# CM4_ICFG register map
Vendor: Texas Instruments
Peripheral module from a debugger description file (folder am273).
Registers are 32-bit, read-only, no defined reset value unless marked. A register's access mark holds for its fields unless they carry their own. Offsets are as the file gives them; lines under a group give offsets from that group; [hi:lo] are bit positions; {n}, {i} and the like mark numbered series; 'fields as' and 'values as' point back to an identical list; <NAME> marks a mode.

## CM4_ICFG
0x00 CMX_ITM_STIM0 rw — http://infocenter.arm.com/help/topic/com.arm.doc.ddi0439b/DDI0439B_cortex_m4_r0p0_trm.pdf
  [31:0] ITM_STIM0 — RW - ITM_STIM0
0x7C CMX_ITM_STIM31 rw — http://infocenter.arm.com/help/topic/com.arm.doc.ddi0439b/DDI0439B_cortex_m4_r0p0_trm.pdf
  [31:0] ITM_STIM31 — RW - ITM_STIM31
0xE00 CMX_ITM_TER rw — http://infocenter.arm.com/help/topic/com.arm.doc.ddi0439b/DDI0439B_cortex_m4_r0p0_trm.pdf
  [31:0] ITM_TER — RW 0x00000000 Trace Enable Register
0xE40 CMX_ITM_TPR rw — http://infocenter.arm.com/help/topic/com.arm.doc.ddi0439b/DDI0439B_cortex_m4_r0p0_trm.pdf
  [31:0] ITM_TPR — RW 0x00000000 ITM Trace Privilege Register, ITM_TPR on page 10-5
0xE80 CMX_ITM_TCR rw — http://infocenter.arm.com/help/topic/com.arm.doc.ddi0439b/DDI0439B_cortex_m4_r0p0_trm.pdf
  [31:0] ITM_TCR — RW 0x00000000 Trace Control Register
0xEF8 CMX_ITM_IWR access per field — ITM Integration Write Register (privileged access only)
  [0] ATVALIDM rw — Write Only. Only use with integration test (on-chip connectivity test). Do not use in normal applications. When in integration test mode, i.e., bit 0 of ITM->IMCR is set, this bit is used to control the ATVALIDM output of the ATB (trace bus)
0xEFC CMX_ITM_IRR — ITM Integration Read Register (privileged access only)
  [0] ATREADYM — Only use with integration test (on-chip connectivity test). Do not use in normal applications. When in integration test mode, i.e. bit 0 of ITM->IMCR is set, this bit is used to read the ATREADYM input of the ATB (trace bus)
0xF00 CMX_ITM_IMCR access per field — ITM Integration Mode Control Register (privileged access only)
  [0] INTEGRATION rw — Only use with integration test (on-chip connectivity test). Do not use in normal applications. Set to 1 to enable integration test mode.
0xFB0 CMX_LAR rw — https://static.docs.arm.com/ihi0029/e/coresight_v3_0_architecture_specification_IHI0029E.pdf?_ga=2.243641541.19024475.1571741864-233759942.1562499274
  [31:0] KEY — Writing a value to this field controls write access to the other registers in the component. Permitted values of KEY are: Write 0xC5ACCE55 Signals that LSR must permit writing to the other registers in the component. Write any other value Signals that LSR must block writing to the other registers in the component.
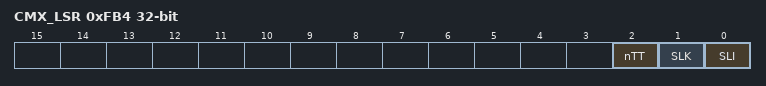
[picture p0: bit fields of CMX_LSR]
0xFB4 CMX_LSR access per field — https://static.docs.arm.com/ihi0029/e/coresight_v3_0_architecture_specification_IHI0029E.pdf?_ga=2.243641541.19024475.1571741864-233759942.1562499274
  [2] nTT rw — This bit is always zero, which indicates that the component implements a 32-bit LAR
  [1] SLK rw — This field is used to return the current software lock status. Permitted values of SLK are: 0 Writing to the other registers in the component is permitted. 1 Writing to the other registers in the component is blocked.
  [0] SLI rw — This field indicates whether a Software lock mechanism is implemented. Permitted values of SLI are: 0 Software lock mechanism is not implemented. 1 Software lock mechanism is implemented.
0xFD0 CMX_ITM_PID4 — http://infocenter.arm.com/help/topic/com.arm.doc.ddi0439b/DDI0439B_cortex_m4_r0p0_trm.pdf
  [31:0] ITM_PID4 — RO 0x00000004 Peripheral Identification registers
{0xFC0+4i} CMX_ITM_PID{i} (i=5..7) — http://infocenter.arm.com/help/topic/com.arm.doc.ddi0439b/DDI0439B_cortex_m4_r0p0_trm.pdf
  [31:0] ITM_PID{i} — RO 0x00000000
0xFE0 CMX_ITM_PID0 — http://infocenter.arm.com/help/topic/com.arm.doc.ddi0439b/DDI0439B_cortex_m4_r0p0_trm.pdf
  [31:0] ITM_PID0 — RO 0x00000001
0xFE4 CMX_ITM_PID1 — http://infocenter.arm.com/help/topic/com.arm.doc.ddi0439b/DDI0439B_cortex_m4_r0p0_trm.pdf
  [31:0] ITM_PID1 — RO 0x000000B0
0xFE8 CMX_ITM_PID2 — http://infocenter.arm.com/help/topic/com.arm.doc.ddi0439b/DDI0439B_cortex_m4_r0p0_trm.pdf
  [31:0] ITM_PID2 — RO 0x0000003B
0xFEC CMX_ITM_PID3 — http://infocenter.arm.com/help/topic/com.arm.doc.ddi0439b/DDI0439B_cortex_m4_r0p0_trm.pdf
  [31:0] ITM_PID3 — RO 0x00000000
0xFF0 CMX_ITM_CID0 — http://infocenter.arm.com/help/topic/com.arm.doc.ddi0439b/DDI0439B_cortex_m4_r0p0_trm.pdf
  [31:0] ITM_CID0 — RO 0x0000000D Component Identification registers
0xFF4 CMX_ITM_CID1 — http://infocenter.arm.com/help/topic/com.arm.doc.ddi0439b/DDI0439B_cortex_m4_r0p0_trm.pdf
  [31:0] ITM_CID1 — RO 0x000000E0
0xFF8 CMX_ITM_CID2 — http://infocenter.arm.com/help/topic/com.arm.doc.ddi0439b/DDI0439B_cortex_m4_r0p0_trm.pdf
  [31:0] ITM_CID2 — RO 0x00000005
0xFFC CMX_ITM_CID3 — http://infocenter.arm.com/help/topic/com.arm.doc.ddi0439b/DDI0439B_cortex_m4_r0p0_trm.pdf
  [31:0] ITM_CID3 — RO 0x000000B1
0x1000 CMX_DWT_CTRL rw — http://infocenter.arm.com/help/topic/com.arm.doc.ddi0439b/DDI0439B_cortex_m4_r0p0_trm.pdf
  [31:0] DWT_CTRL — RW See a Control Register
0x1004 CMX_DWT_CYCCNT rw — http://infocenter.arm.com/help/topic/com.arm.doc.ddi0439b/DDI0439B_cortex_m4_r0p0_trm.pdf
  [31:0] DWT_CYCCNT — RW 0x00000000 Cycle Count Register
0x1008 CMX_DWT_CPICNT rw — http://infocenter.arm.com/help/topic/com.arm.doc.ddi0439b/DDI0439B_cortex_m4_r0p0_trm.pdf
  [31:0] DWT_CPICNT — RW - CPI Count Register
0x100C CMX_DWT_EXCCNT rw — http://infocenter.arm.com/help/topic/com.arm.doc.ddi0439b/DDI0439B_cortex_m4_r0p0_trm.pdf
  [31:0] DWT_EXCCNT — RW - Exception Overhead Count Register
0x1010 CMX_DWT_SLEEPCNT rw — http://infocenter.arm.com/help/topic/com.arm.doc.ddi0439b/DDI0439B_cortex_m4_r0p0_trm.pdf
  [31:0] DWT_SLEEPCNT — RW - Sleep Count Register
0x1014 CMX_DWT_LSUCNT rw — http://infocenter.arm.com/help/topic/com.arm.doc.ddi0439b/DDI0439B_cortex_m4_r0p0_trm.pdf
  [31:0] DWT_LSUCNT — RW - LSU Count Register
0x1018 CMX_DWT_FOLDCNT rw — http://infocenter.arm.com/help/topic/com.arm.doc.ddi0439b/DDI0439B_cortex_m4_r0p0_trm.pdf
  [31:0] DWT_FOLDCNT — RW - Folded-instruction Count Register
0x101C CMX_DWT_PCSR — http://infocenter.arm.com/help/topic/com.arm.doc.ddi0439b/DDI0439B_cortex_m4_r0p0_trm.pdf
  [31:0] DWT_PCSR — RO - Program Counter Sample Register
{0x1020+0x10*i} CMX_DWT_COMP{i} rw (i=0..3) — http://infocenter.arm.com/help/topic/com.arm.doc.ddi0439b/DDI0439B_cortex_m4_r0p0_trm.pdf
  [31:0] DWT_COMP{i} — RW - Comparator Register{i}
{0x1024+0x10*i} CMX_DWT_MASK{i} rw (i=0..3) — http://infocenter.arm.com/help/topic/com.arm.doc.ddi0439b/DDI0439B_cortex_m4_r0p0_trm.pdf
  [31:0] DWT_MASK{i} — RW - Mask Register{i}
{0x1028+0x10*i} CMX_DWT_FUNCTION{i} rw (i=0..3) — http://infocenter.arm.com/help/topic/com.arm.doc.ddi0439b/DDI0439B_cortex_m4_r0p0_trm.pdf
  [31:0] DWT_FUNCTION{i} — RW 0x00000000 Function Register{i}
0x1FD0 CMX_DWT_PID4 — http://infocenter.arm.com/help/topic/com.arm.doc.ddi0439b/DDI0439B_cortex_m4_r0p0_trm.pdf
  [31:0] DWT_PID4 — RO 0x04 Peripheral identification registers
{0x1FC0+4i} CMX_DWT_PID{i} (i=5..7) — http://infocenter.arm.com/help/topic/com.arm.doc.ddi0439b/DDI0439B_cortex_m4_r0p0_trm.pdf
  [31:0] DWT_PID{i} — RO 0x00
0x1FE0 CMX_DWT_PID0 — http://infocenter.arm.com/help/topic/com.arm.doc.ddi0439b/DDI0439B_cortex_m4_r0p0_trm.pdf
  [31:0] DWT_PID0 — RO 0x02
0x1FE4 CMX_DWT_PID1 — http://infocenter.arm.com/help/topic/com.arm.doc.ddi0439b/DDI0439B_cortex_m4_r0p0_trm.pdf
  [31:0] DWT_PID1 — RO 0xB0
0x1FE8 CMX_DWT_PID2 — http://infocenter.arm.com/help/topic/com.arm.doc.ddi0439b/DDI0439B_cortex_m4_r0p0_trm.pdf
  [31:0] DWT_PID2 — RO 0x3B
0x1FEC CMX_DWT_PID3 — http://infocenter.arm.com/help/topic/com.arm.doc.ddi0439b/DDI0439B_cortex_m4_r0p0_trm.pdf
  [31:0] DWT_PID3 — RO 0x00
0x1FF0 CMX_DWT_CID0 — http://infocenter.arm.com/help/topic/com.arm.doc.ddi0439b/DDI0439B_cortex_m4_r0p0_trm.pdf
  [31:0] DWT_CID0 — RO 0x0D Component identification registers
0x1FF4 CMX_DWT_CID1 — http://infocenter.arm.com/help/topic/com.arm.doc.ddi0439b/DDI0439B_cortex_m4_r0p0_trm.pdf
  [31:0] DWT_CID1 — RO 0xE0
0x1FF8 CMX_DWT_CID2 — http://infocenter.arm.com/help/topic/com.arm.doc.ddi0439b/DDI0439B_cortex_m4_r0p0_trm.pdf
  [31:0] DWT_CID2 — RO 0x05
0x1FFC CMX_DWT_CID3 — http://infocenter.arm.com/help/topic/com.arm.doc.ddi0439b/DDI0439B_cortex_m4_r0p0_trm.pdf
  [31:0] DWT_CID3 — RO 0xB1
0x2000 CMX_FP_CTRL rw — http://infocenter.arm.com/help/topic/com.arm.doc.ddi0439b/DDI0439B_cortex_m4_r0p0_trm.pdf
  [31:0] FP_CTRL — RW 0x130 FlashPatch Control Register
0x2004 CMX_FP_REMAP rw — http://infocenter.arm.com/help/topic/com.arm.doc.ddi0439b/DDI0439B_cortex_m4_r0p0_trm.pdf
  [31:0] FP_REMAP — RW - FlashPatch Remap Register
0x2008 CMX_FP_COMP0 rw — http://infocenter.arm.com/help/topic/com.arm.doc.ddi0439b/DDI0439B_cortex_m4_r0p0_trm.pdf
  [31:0] FP_COMP0 — RW 1'b0a . For FP_COMP0 to FP_COMP7, bit 0 is reset to 0. Other bits in these registers are FlashPatch Comparator Register0
{0x2008+4i} CMX_FP_COMP{i} rw (i=1..7) — http://infocenter.arm.com/help/topic/com.arm.doc.ddi0439b/DDI0439B_cortex_m4_r0p0_trm.pdf
  [31:0] FP_COMP{i} — RW 1'b0 FlashPatch Comparator Register{i}
0x2FD0 CMX_FP_PID4 — http://infocenter.arm.com/help/topic/com.arm.doc.ddi0439b/DDI0439B_cortex_m4_r0p0_trm.pdf
  [31:0] FP_PID4 — RO 0x04 Peripheral identification registers
{0x2FC0+4i} CMX_FP_PID{i} (i=5..7) — http://infocenter.arm.com/help/topic/com.arm.doc.ddi0439b/DDI0439B_cortex_m4_r0p0_trm.pdf
  [31:0] FP_PID{i} — RO 0x00
0x2FE0 CMX_FP_PID0 — http://infocenter.arm.com/help/topic/com.arm.doc.ddi0439b/DDI0439B_cortex_m4_r0p0_trm.pdf
  [31:0] FP_PID0 — RO 0x03
0x2FE4 CMX_FP_PID1 — http://infocenter.arm.com/help/topic/com.arm.doc.ddi0439b/DDI0439B_cortex_m4_r0p0_trm.pdf
  [31:0] FP_PID1 — RO 0xB0
0x2FE8 CMX_FP_PID2 — http://infocenter.arm.com/help/topic/com.arm.doc.ddi0439b/DDI0439B_cortex_m4_r0p0_trm.pdf
  [31:0] FP_PID2 — RO 0x2B
0x2FEC CMX_FP_PID3 — http://infocenter.arm.com/help/topic/com.arm.doc.ddi0439b/DDI0439B_cortex_m4_r0p0_trm.pdf
  [31:0] FP_PID3 — RO 0x00
0x2FF0 CMX_FP_CID0 — http://infocenter.arm.com/help/topic/com.arm.doc.ddi0439b/DDI0439B_cortex_m4_r0p0_trm.pdf
  [31:0] FP_CID0 — RO 0x0D Component identification registers
0x2FF4 CMX_FP_CID1 — http://infocenter.arm.com/help/topic/com.arm.doc.ddi0439b/DDI0439B_cortex_m4_r0p0_trm.pdf
  [31:0] FP_CID1 — RO 0xE0
0x2FF8 CMX_FP_CID2 — http://infocenter.arm.com/help/topic/com.arm.doc.ddi0439b/DDI0439B_cortex_m4_r0p0_trm.pdf
  [31:0] FP_CID2 — RO 0x05
0x2FFC CMX_FP_CID3 — http://infocenter.arm.com/help/topic/com.arm.doc.ddi0439b/DDI0439B_cortex_m4_r0p0_trm.pdf
  [31:0] FP_CID3 — RO 0xB1
0xE008 CMX_ACTLR rw — http://infocenter.arm.com/help/topic/com.arm.doc.ddi0439b/DDI0439B_cortex_m4_r0p0_trm.pdf
  [31:0] ACTLR — RW 0x00000000 Auxiliary Control Register, ACTLR on page 4-5
0xE010 CMX_STCSR rw — http://infocenter.arm.com/help/topic/com.arm.doc.ddi0439b/DDI0439B_cortex_m4_r0p0_trm.pdf
  [31:0] STCSR — RW 0x00000000 SysTick Control and Status Register
0xE014 CMX_STRVR rw — http://infocenter.arm.com/help/topic/com.arm.doc.ddi0439b/DDI0439B_cortex_m4_r0p0_trm.pdf
  [31:0] STRVR — RW Unknown SysTick Reload Value Register
0xE018 CMX_STCVR rw — http://infocenter.arm.com/help/topic/com.arm.doc.ddi0439b/DDI0439B_cortex_m4_r0p0_trm.pdf
  [31:0] STCVR — RW clear Unknown SysTick Current Value Register
0xE01C CMX_STCR — http://infocenter.arm.com/help/topic/com.arm.doc.ddi0439b/DDI0439B_cortex_m4_r0p0_trm.pdf
  [31:0] STCR — RO STCALIB SysTick Calibration Value Register
0xED00 CMX_CPUID — http://infocenter.arm.com/help/topic/com.arm.doc.ddi0439b/DDI0439B_cortex_m4_r0p0_trm.pdf
  [31:0] CPUID — RO 0x410FC240 CPUID Base Register, CPUID on page 4-5
0xED04 CMX_ICSR rw — http://infocenter.arm.com/help/topic/com.arm.doc.ddi0439b/DDI0439B_cortex_m4_r0p0_trm.pdf
  [31:0] ICSR — RW or RO 0x00000000 Interrupt Control and State Register
0xED08 CMX_VTOR rw — http://infocenter.arm.com/help/topic/com.arm.doc.ddi0439b/DDI0439B_cortex_m4_r0p0_trm.pdf
  [31:0] VTOR — RW 0x00000000 Vector Table Offset Register
0xED0C CMX_AIRCR rw — http://infocenter.arm.com/help/topic/com.arm.doc.ddi0439b/DDI0439B_cortex_m4_r0p0_trm.pdf
  [31:0] AIRCR — RW 0x00000000a Application Interrupt and Reset Control Register
0xED10 CMX_SCR rw — http://infocenter.arm.com/help/topic/com.arm.doc.ddi0439b/DDI0439B_cortex_m4_r0p0_trm.pdf
  [31:0] SCR — RW 0x00000000 System Control Register
0xED14 CMX_CCR rw — http://infocenter.arm.com/help/topic/com.arm.doc.ddi0439b/DDI0439B_cortex_m4_r0p0_trm.pdf
  [31:0] CCR — RW 0x00000200 Configuration and Control Register.
{0xED14+4i} CMX_SHPR{i} rw (i=1..3) — http://infocenter.arm.com/help/topic/com.arm.doc.ddi0439b/DDI0439B_cortex_m4_r0p0_trm.pdf
  [31:0] SHPR{i} — RW 0x00000000 System Handler Priority Register {i}
0xED24 CMX_SHCSR rw — http://infocenter.arm.com/help/topic/com.arm.doc.ddi0439b/DDI0439B_cortex_m4_r0p0_trm.pdf
  [31:0] SHCSR — RW 0x00000000 System Handler Control and State Register
0xED28 CMX_CFSR rw — http://infocenter.arm.com/help/topic/com.arm.doc.ddi0439b/DDI0439B_cortex_m4_r0p0_trm.pdf
  [31:0] CFSR — RW 0x00000000 Configurable Fault Status Registers
0xED2C CMX_HFSR rw — http://infocenter.arm.com/help/topic/com.arm.doc.ddi0439b/DDI0439B_cortex_m4_r0p0_trm.pdf
  [31:0] HFSR — RW 0x00000000 HardFault Status register
0xED30 CMX_DFSR rw — http://infocenter.arm.com/help/topic/com.arm.doc.ddi0439b/DDI0439B_cortex_m4_r0p0_trm.pdf
  [31:0] DFSR — RW 0x00000000 Debug Fault Status Register
0xED34 CMX_MMFAR rw — http://infocenter.arm.com/help/topic/com.arm.doc.ddi0439b/DDI0439B_cortex_m4_r0p0_trm.pdf
  [31:0] MMFAR — RW Unknown MemManage Address Registerb
0xED38 CMX_BFAR rw — http://infocenter.arm.com/help/topic/com.arm.doc.ddi0439b/DDI0439B_cortex_m4_r0p0_trm.pdf
  [31:0] BFAR — RW Unknown BusFault Address Registerb
0xED3C CMX_AFSR rw — http://infocenter.arm.com/help/topic/com.arm.doc.ddi0439b/DDI0439B_cortex_m4_r0p0_trm.pdf
  [31:0] AFSR — RW 0x00000000 Auxiliary Fault Status Register, AFSR on page 4-6
0xED40 CMX_ID_PFR0 — http://infocenter.arm.com/help/topic/com.arm.doc.ddi0439b/DDI0439B_cortex_m4_r0p0_trm.pdf
  [31:0] ID_PFR0 — RO 0x00000030 Processor Feature Register 0
0xED44 CMX_ID_PFR1 — http://infocenter.arm.com/help/topic/com.arm.doc.ddi0439b/DDI0439B_cortex_m4_r0p0_trm.pdf
  [31:0] ID_PFR1 — RO 0x00000200 Processor Feature Register 1
0xED48 CMX_ID_DFR0 — http://infocenter.arm.com/help/topic/com.arm.doc.ddi0439b/DDI0439B_cortex_m4_r0p0_trm.pdf
  [31:0] ID_DFR0 — RO 0x00100000 Debug Features Register 0
0xED4C CMX_ID_AFR0 — http://infocenter.arm.com/help/topic/com.arm.doc.ddi0439b/DDI0439B_cortex_m4_r0p0_trm.pdf
  [31:0] ID_AFR0 — RO 0x00000000 Auxiliary Features Register 0
0xED50 CMX_ID_MMFR0 — http://infocenter.arm.com/help/topic/com.arm.doc.ddi0439b/DDI0439B_cortex_m4_r0p0_trm.pdf
  [31:0] ID_MMFR0 — RO 0x00000030 Memory Model Feature Register 0
{0xED50+4i} CMX_ID_MMFR{i} (i=1..3) — http://infocenter.arm.com/help/topic/com.arm.doc.ddi0439b/DDI0439B_cortex_m4_r0p0_trm.pdf
  [31:0] ID_MMFR{i} — RO 0x00000000 Memory Model Feature Register {i}
0xED60 CMX_ID_ISAR0 — http://infocenter.arm.com/help/topic/com.arm.doc.ddi0439b/DDI0439B_cortex_m4_r0p0_trm.pdf
  [31:0] ID_ISAR0 — RO 0x01141110 Instruction Set Attributes Register 0
0xED64 CMX_ID_ISAR1 — http://infocenter.arm.com/help/topic/com.arm.doc.ddi0439b/DDI0439B_cortex_m4_r0p0_trm.pdf
  [31:0] ID_ISAR1 — RO 0x02112000 Instruction Set Attributes Register 1
0xED68 CMX_ID_ISAR2 — http://infocenter.arm.com/help/topic/com.arm.doc.ddi0439b/DDI0439B_cortex_m4_r0p0_trm.pdf
  [31:0] ID_ISAR2 — RO 0x21232231 Instruction Set Attributes Register 2
0xED6C CMX_ID_ISAR3 — http://infocenter.arm.com/help/topic/com.arm.doc.ddi0439b/DDI0439B_cortex_m4_r0p0_trm.pdf
  [31:0] ID_ISAR3 — RO 0x01111131 Instruction Set Attributes Register 3
0xED70 CMX_ID_ISAR4 — http://infocenter.arm.com/help/topic/com.arm.doc.ddi0439b/DDI0439B_cortex_m4_r0p0_trm.pdf
  [31:0] ID_ISAR4 — RO 0x01310102 Instruction Set Attributes Register 4
0xED88 CMX_CPACR rw — http://infocenter.arm.com/help/topic/com.arm.doc.ddi0439b/DDI0439B_cortex_m4_r0p0_trm.pdf
  [31:0] CPACR — RW - Coprocessor Access Control Register
0xEDF0 CMX_DHCSR rw — http://infocenter.arm.com/help/topic/com.arm.doc.ddi0439b/DDI0439B_cortex_m4_r0p0_trm.pdf
  [31:0] DHCSR — RW -- DBG -- Debug Halt Control and Status Register
0xEDF4 CMX_DCRSR wo — http://infocenter.arm.com/help/topic/com.arm.doc.ddi0439b/DDI0439B_cortex_m4_r0p0_trm.pdf
  [31:0] DCRSR — W -- DBG -- Debug Core Register Selector Register
0xEDF8 CMX_DCRDR rw — http://infocenter.arm.com/help/topic/com.arm.doc.ddi0439b/DDI0439B_cortex_m4_r0p0_trm.pdf
  [31:0] DCRDR — RW -- DBG -- Debug Core Register Data Register
0xEDFC CMX_DEMCR rw — http://infocenter.arm.com/help/topic/com.arm.doc.ddi0439b/DDI0439B_cortex_m4_r0p0_trm.pdf
  [31:0] DEMCR — RW -- DBG -- Debug Exception and Monitor Control Register
0xEF00 CMX_STIR wo — http://infocenter.arm.com/help/topic/com.arm.doc.ddi0439b/DDI0439B_cortex_m4_r0p0_trm.pdf
  [31:0] STIR — WO 0x00000000 Software Triggered Interrupt Register
0x40000 CMX_TPIU_SSPSR — http://infocenter.arm.com/help/topic/com.arm.doc.ddi0439b/DDI0439B_cortex_m4_r0p0_trm.pdf
  [31:0] TPIU_SSPSR — RO 0x0xx Supported Synchronous Port Size Register
0x40004 CMX_TPIU_CSPSR rw — http://infocenter.arm.com/help/topic/com.arm.doc.ddi0439b/DDI0439B_cortex_m4_r0p0_trm.pdf
  [31:0] TPIU_CSPSR — RW 0x01 Current Synchronous Port Size Register
0x40010 CMX_TPIU_ACPR rw — http://infocenter.arm.com/help/topic/com.arm.doc.ddi0439b/DDI0439B_cortex_m4_r0p0_trm.pdf
  [31:0] TPIU_ACPR — RW 0x0000 Asynchronous Clock Prescaler Register, TPIU_ACPR on page 11-6
0x400F0 CMX_TPIU_SPPR rw — http://infocenter.arm.com/help/topic/com.arm.doc.ddi0439b/DDI0439B_cortex_m4_r0p0_trm.pdf
  [31:0] TPIU_SPPR — RW 0x01 Selected Pin Protocol Register
0x40300 CMX_TPIU_FFSR — http://infocenter.arm.com/help/topic/com.arm.doc.ddi0439b/DDI0439B_cortex_m4_r0p0_trm.pdf
  [31:0] TPIU_FFSR — RO 0x08 Formatter and Flush Status Register, TPIU_FFSR on page 11-6
0x40304 CMX_TPIU_FFCR rw — http://infocenter.arm.com/help/topic/com.arm.doc.ddi0439b/DDI0439B_cortex_m4_r0p0_trm.pdf
  [31:0] TPIU_FFCR — RW 0x102 Formatter and Flush Control Register, TPIU_FFCR on page 11-7
0x40308 CMX_TPIU_FSCR — http://infocenter.arm.com/help/topic/com.arm.doc.ddi0439b/DDI0439B_cortex_m4_r0p0_trm.pdf
  [31:0] TPIU_FSCR — RO 0x00 Formatter Synchronization Counter Register
0x40EE8 CMX_TPIU_TRIGGER — http://infocenter.arm.com/help/topic/com.arm.doc.ddi0439b/DDI0439B_cortex_m4_r0p0_trm.pdf
  [31:0] TPIU_TRIGGER — RO 0x0 TRIGGER on page 11-8
0x40EEC CMX_TPIU_FIFO_DATA0 — http://infocenter.arm.com/help/topic/com.arm.doc.ddi0439b/DDI0439B_cortex_m4_r0p0_trm.pdf
  [31:0] TPIU_FIFO_DATA0 — RO 0x--000000 Integration ETM Data on page 11-8
0x40EF0 CMX_TPIU_ITATBCTR2 — http://infocenter.arm.com/help/topic/com.arm.doc.ddi0439b/DDI0439B_cortex_m4_r0p0_trm.pdf
  [31:0] TPIU_ITATBCTR2 — RO 0x0 ITATBCTR2 on page 11-9
0x40EF8 CMX_TPIU_ITATBCTR0 — http://infocenter.arm.com/help/topic/com.arm.doc.ddi0439b/DDI0439B_cortex_m4_r0p0_trm.pdf
  [31:0] TPIU_ITATBCTR0 — RO 0x0 ITATBCTR0 on page 11-11
0x40EFC CMX_TPIU_FIFO_DATA1 — http://infocenter.arm.com/help/topic/com.arm.doc.ddi0439b/DDI0439B_cortex_m4_r0p0_trm.pdf
  [31:0] TPIU_FIFO_DATA1 — RO 0x--000000 Integration ITM Data on page 11-10
0x40F00 CMX_TPIU_ITCTRL rw — http://infocenter.arm.com/help/topic/com.arm.doc.ddi0439b/DDI0439B_cortex_m4_r0p0_trm.pdf
  [31:0] TPIU_ITCTRL — RW 0x0 Integration Mode Control, TPIU_ITCTRL on page 11-11
0x40FA0 CMX_TPIU_CLAIMSET rw — http://infocenter.arm.com/help/topic/com.arm.doc.ddi0439b/DDI0439B_cortex_m4_r0p0_trm.pdf
  [31:0] TPIU_CLAIMSET — RW 0xF Claim tag set
0x40FA4 CMX_TPIU_CLAIMCLR rw — http://infocenter.arm.com/help/topic/com.arm.doc.ddi0439b/DDI0439B_cortex_m4_r0p0_trm.pdf
  [31:0] TPIU_CLAIMCLR — RW 0x0 Claim tag clear
0x40FC8 CMX_TPIU_DEVID — http://infocenter.arm.com/help/topic/com.arm.doc.ddi0439b/DDI0439B_cortex_m4_r0p0_trm.pdf
  [31:0] TPIU_DEVID — RO - TPIU_DEVID on page 11-12
0x40FD0 CMX_TPIU_PID4 — http://infocenter.arm.com/help/topic/com.arm.doc.ddi0439b/DDI0439B_cortex_m4_r0p0_trm.pdf
  [31:0] TPIU_PID4 — RO 0x04 Peripheral identification registers
{0x40FC0+4i} CMX_TPIU_PID{i} (i=5..7) — http://infocenter.arm.com/help/topic/com.arm.doc.ddi0439b/DDI0439B_cortex_m4_r0p0_trm.pdf
  [31:0] TPIU_PID{i} — RO 0x00
0x40FE0 CMX_TPIU_PID0 — http://infocenter.arm.com/help/topic/com.arm.doc.ddi0439b/DDI0439B_cortex_m4_r0p0_trm.pdf
  [31:0] TPIU_PID0 — RO 0xA1
0x40FE4 CMX_TPIU_PID1 — http://infocenter.arm.com/help/topic/com.arm.doc.ddi0439b/DDI0439B_cortex_m4_r0p0_trm.pdf
  [31:0] TPIU_PID1 — RO 0xB9
0x40FE8 CMX_TPIU_PID2 — http://infocenter.arm.com/help/topic/com.arm.doc.ddi0439b/DDI0439B_cortex_m4_r0p0_trm.pdf
  [31:0] TPIU_PID2 — RO 0x0B
0x40FEC CMX_TPIU_PID3 — http://infocenter.arm.com/help/topic/com.arm.doc.ddi0439b/DDI0439B_cortex_m4_r0p0_trm.pdf
  [31:0] TPIU_PID3 — RO 0x00
0x40FF0 CMX_TPIU_CID0 — http://infocenter.arm.com/help/topic/com.arm.doc.ddi0439b/DDI0439B_cortex_m4_r0p0_trm.pdf
  [31:0] TPIU_CID0 — RO 0x0D Component identification registers
0x40FF4 CMX_TPIU_CID1 — http://infocenter.arm.com/help/topic/com.arm.doc.ddi0439b/DDI0439B_cortex_m4_r0p0_trm.pdf
  [31:0] TPIU_CID1 — RO 0x90
0x40FF8 CMX_TPIU_CID2 — http://infocenter.arm.com/help/topic/com.arm.doc.ddi0439b/DDI0439B_cortex_m4_r0p0_trm.pdf
  [31:0] TPIU_CID2 — RO 0x05
0x40FFC CMX_TPIU_CID3 — http://infocenter.arm.com/help/topic/com.arm.doc.ddi0439b/DDI0439B_cortex_m4_r0p0_trm.pdf
  [31:0] TPIU_CID3 — RO 0xB1
0xFF000 CMX_SCS rw — http://infocenter.arm.com/help/topic/com.arm.doc.ddi0439b/DDI0439B_cortex_m4_r0p0_trm.pdf
  [31:0] SCS — SCS 0xFFF0F003 See System Control Space on page 8-4
0xFF004 CMX_DWT rw — http://infocenter.arm.com/help/topic/com.arm.doc.ddi0439b/DDI0439B_cortex_m4_r0p0_trm.pdf
  [31:0] DWT — DWT 0xFFF02003 a See Table 9-1 on page 9-4
0xFF008 CMX_FPB rw — http://infocenter.arm.com/help/topic/com.arm.doc.ddi0439b/DDI0439B_cortex_m4_r0p0_trm.pdf
  [31:0] FPB — FPB 0xFFF03003 b See Table 8-7 on page 8-10
0xFF00C CMX_ITM rw — http://infocenter.arm.com/help/topic/com.arm.doc.ddi0439b/DDI0439B_cortex_m4_r0p0_trm.pdf
  [31:0] ITM — ITM 0xFFF01003 c See Table 10-1 on page 10-4
0xFF010 CMX_TPIU rw — http://infocenter.arm.com/help/topic/com.arm.doc.ddi0439b/DDI0439B_cortex_m4_r0p0_trm.pdf
  [31:0] TPIU — TPIU 0xFFF41003d See Table 11-1 on page 11-5
0xFF014 CMX_ETM rw — http://infocenter.arm.com/help/topic/com.arm.doc.ddi0439b/DDI0439B_cortex_m4_r0p0_trm.pdf
  [31:0] ETM — ETM 0xFFF42003e See the ETM-M4 Technical Reference Manual.
0xFF018 CMX_ENDMARKER rw — http://infocenter.arm.com/help/topic/com.arm.doc.ddi0439b/DDI0439B_cortex_m4_r0p0_trm.pdf
  [31:0] ENDMARKER — End marker 0x00000000 See DAP accessible ROM table in the ARMv7-M Architectural Reference Manual
0xFFFCC CMX_SYSACCESS rw — http://infocenter.arm.com/help/topic/com.arm.doc.ddi0439b/DDI0439B_cortex_m4_r0p0_trm.pdf
  [31:0] SYSACCESS — SYSTEM ACCESS 0x00000001
0xFFFD0 CMX_PeripheralID4 — http://infocenter.arm.com/help/topic/com.arm.doc.ddi0439b/DDI0439B_cortex_m4_r0p0_trm.pdf
  [31:0] PeripheralID4 — PeripheralID4 0x00000004
0xFFFE0 CMX_PeripheralID0 — http://infocenter.arm.com/help/topic/com.arm.doc.ddi0439b/DDI0439B_cortex_m4_r0p0_trm.pdf
  [31:0] PeripheralID0 — PeripheralID0 0x000000C4
0xFFFE4 CMX_PeripheralID1 — http://infocenter.arm.com/help/topic/com.arm.doc.ddi0439b/DDI0439B_cortex_m4_r0p0_trm.pdf
  [31:0] PeripheralID1 — PeripheralID1 0x000000B4
0xFFFE8 CMX_PeripheralID2 — http://infocenter.arm.com/help/topic/com.arm.doc.ddi0439b/DDI0439B_cortex_m4_r0p0_trm.pdf
  [31:0] PeripheralID2 — PeripheralID2 0x0000000B
0xFFFEC CMX_PeripheralID3 — http://infocenter.arm.com/help/topic/com.arm.doc.ddi0439b/DDI0439B_cortex_m4_r0p0_trm.pdf
  [31:0] PeripheralID3 — PeripheralID3 0x00000000
0xFFFF0 CMX_ComponentID0 — http://infocenter.arm.com/help/topic/com.arm.doc.ddi0439b/DDI0439B_cortex_m4_r0p0_trm.pdf
  [31:0] ComponentID0 — ComponentID0 0x0000000D
0xFFFF4 CMX_ComponentID1 — http://infocenter.arm.com/help/topic/com.arm.doc.ddi0439b/DDI0439B_cortex_m4_r0p0_trm.pdf
  [31:0] ComponentID1 — ComponentID1 0x00000010
0xFFFF8 CMX_ComponentID2 — http://infocenter.arm.com/help/topic/com.arm.doc.ddi0439b/DDI0439B_cortex_m4_r0p0_trm.pdf
  [31:0] ComponentID2 — ComponentID2 0x00000005
0xFFFFC CMX_ComponentID3 — http://infocenter.arm.com/help/topic/com.arm.doc.ddi0439b/DDI0439B_cortex_m4_r0p0_trm.pdf
  [31:0] ComponentID3 — ComponentID3 0x000000B1
